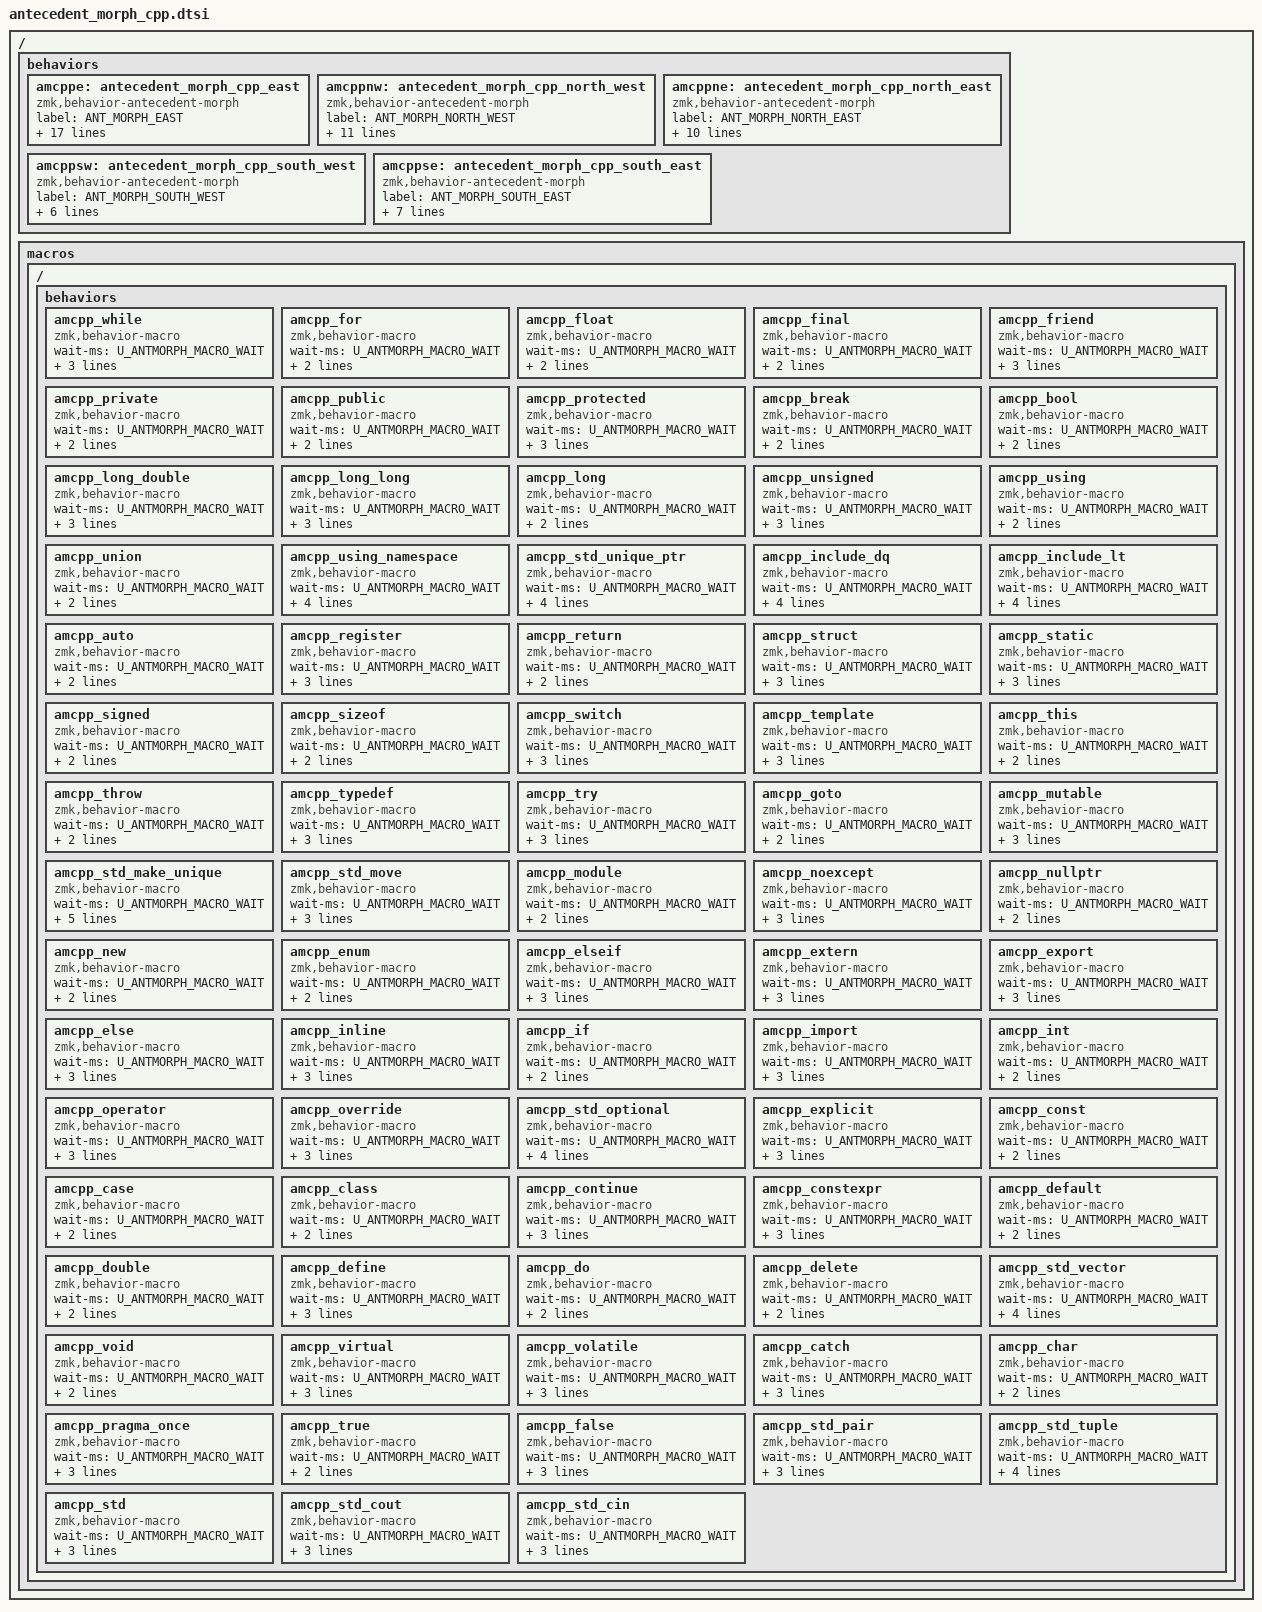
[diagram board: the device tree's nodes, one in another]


/ {
    behaviors {
        amcppe: antecedent_morph_cpp_east {
            compatible = "zmk,behavior-antecedent-morph";
            label = "ANT_MORPH_EAST";
            #binding-cells = <0>;
            defaults = <&none>;
            bindings = <&amcpp_while>, <&amcpp_float>, <&amcpp_public>, <&amcpp_bool>, <&amcpp_long_long>, <&amcpp_using>, 
                        <&amcpp_auto>, <&amcpp_return>, <&amcpp_static>, <&amcpp_this>, <&amcpp_goto>, <&amcpp_std_make_unique>, <&amcpp_nullptr>, <&amcpp_elseif>, <&amcpp_if>, <&amcpp_std_optional>,
                        <&amcpp_explicit>, <&amcpp_const>, <&amcpp_double>, <&amcpp_void>, <&amcpp_catch>, <&amcpp_std_cin>, <&amcpp_std_cout>,
                        <&kp EQUAL>, <&kp EQUAL>, <&kp EQUAL>, <&kp EQUAL>, <&kp EQUAL>, <&kp EQUAL>, <&kp EQUAL>, <&kp EQUAL>, <&amcpp_pragma_once>,
                        <&amcpp_false>, <&amcpp_true>, <&amcpp_std_pair>, <&amcpp_std_tuple>,
                        <&amcpp_std>;
            antecedents = <  W F P B   L U 
                            A R S T G M N E I O
                                X C D V   H DOT COMMA
                            PLUS MINUS EXCLAMATION ASTERISK PIPE PERCENT CARET AMPERSAND LS(N3)
                            N0 N1 N2 N3
                            LS(SEMI)>;
            max-delay-ms = <U_ANTMORPH_DELAY>;
        };
        amcppnw: antecedent_morph_cpp_north_west {
            compatible = "zmk,behavior-antecedent-morph";
            label = "ANT_MORPH_NORTH_WEST";
            #binding-cells = <0>;
            defaults = <&none>;
            bindings = <&amcpp_friend>, <&amcpp_protected>, <&amcpp_long>, <&amcpp_std_unique_ptr>, <&amcpp_include_lt>,
                        <&amcpp_switch>, <&amcpp_try>, <&amcpp_std_move>, <&amcpp_new>, <&amcpp_else>, <&amcpp_int>, <&amcpp_override>,
                        <&amcpp_constexpr>, <&amcpp_delete>, <&amcpp_volatile>, <&amcpp_char>, <&kp EQUAL>, <&kp EQUAL>, <&kp EQUAL>;
            antecedents = <    F P     L U   SQT
                                S T   M N E I O
                                C D V   H DOT COMMA SLASH>;
            max-delay-ms = <U_ANTMORPH_DELAY>;
        };
        amcppne: antecedent_morph_cpp_north_east {
            compatible = "zmk,behavior-antecedent-morph";
            label = "ANT_MORPH_NORTH_EAST";
            #binding-cells = <0>;
            defaults = <&none>;
            bindings = <&amcpp_for>, <&amcpp_private>, <&amcpp_break>, <&amcpp_long_double>, <&amcpp_unsigned>, <&amcpp_include_dq>,
                        <&amcpp_register>, <&amcpp_struct>, <&amcpp_template>, <&amcpp_module>, <&amcpp_enum>, <&amcpp_inline>, <&amcpp_operator>,
                        <&amcpp_case>, <&amcpp_default>, <&amcpp_std_vector>;
            antecedents = <    F P B   L U   SQT
                                R S T   M   E I O
                                C D V>;
            max-delay-ms = <U_ANTMORPH_DELAY>;
        };
        amcppsw: antecedent_morph_cpp_south_west {
            compatible = "zmk,behavior-antecedent-morph";
            label = "ANT_MORPH_SOUTH_WEST";
            #binding-cells = <0>;
            defaults = <&none>;
            bindings = <&amcpp_using_namespace>,
                        <&amcpp_sizeof>, <&amcpp_typedef>, <&amcpp_export>,
                        <&amcpp_continue>, <&amcpp_do>;
            antecedents = <              U     
                                S T       E     
                                C D>;
            max-delay-ms = <U_ANTMORPH_DELAY>;
        };
        amcppse: antecedent_morph_cpp_south_east {
            compatible = "zmk,behavior-antecedent-morph";
            label = "ANT_MORPH_SOUTH_EAST";
            #binding-cells = <0>;
            defaults = <&none>;
            bindings = <&amcpp_final>, <&amcpp_union>,
                        <&amcpp_signed>, <&amcpp_throw>, <&amcpp_mutable>, <&amcpp_extern>, <&amcpp_import>,
                        <&amcpp_class>, <&amcpp_define>, <&amcpp_virtual>;
            antecedents = <    F         U      
                                S T   M   E I
                                C D V>;
            max-delay-ms = <U_ANTMORPH_DELAY>;
        };
    };
    macros {
        ZMK_MACRO(amcpp_while,
            wait-ms = <U_ANTMORPH_MACRO_WAIT>;
            tap-ms = <U_ANTMORPH_MACRO_TAP>;
            bindings = <&kp H &kp I &kp L &kp E &kp SPACE &kp LPAR>; // (w)hile (
        )
        ZMK_MACRO(amcpp_for,
            wait-ms = <U_ANTMORPH_MACRO_WAIT>;
            tap-ms = <U_ANTMORPH_MACRO_TAP>;
            bindings = <&kp O &kp R &kp SPACE &kp LPAR>; // (f)or (
        )
        ZMK_MACRO(amcpp_float,
            wait-ms = <U_ANTMORPH_MACRO_WAIT>;
            tap-ms = <U_ANTMORPH_MACRO_TAP>;
            bindings = <&kp L &kp O &kp A &kp T>; // (f)loat
        )
        ZMK_MACRO(amcpp_final,
            wait-ms = <U_ANTMORPH_MACRO_WAIT>;
            tap-ms = <U_ANTMORPH_MACRO_TAP>;
            bindings = <&kp I &kp N &kp A &kp L>; // (f)inal
        )
        ZMK_MACRO(amcpp_friend,
            wait-ms = <U_ANTMORPH_MACRO_WAIT>;
            tap-ms = <U_ANTMORPH_MACRO_TAP>;
            bindings = <&kp R &kp I &kp E &kp N &kp D &kp SPACE>; // (f)riend 
        )
        ZMK_MACRO(amcpp_private,
            wait-ms = <U_ANTMORPH_MACRO_WAIT>;
            tap-ms = <U_ANTMORPH_MACRO_TAP>;
            bindings = <&kp R &kp I &kp V &kp A &kp T &kp E>; // (p)rivate
        )
        ZMK_MACRO(amcpp_public,
            wait-ms = <U_ANTMORPH_MACRO_WAIT>;
            tap-ms = <U_ANTMORPH_MACRO_TAP>;
            bindings = <&kp U &kp B &kp L &kp I &kp C>; // (p)ublic
        )
        ZMK_MACRO(amcpp_protected,
            wait-ms = <U_ANTMORPH_MACRO_WAIT>;
            tap-ms = <U_ANTMORPH_MACRO_TAP>;
            bindings = <&kp R &kp O &kp T &kp E &kp C &kp T &kp E &kp D>; // (p)rotected
        )
        ZMK_MACRO(amcpp_break,
            wait-ms = <U_ANTMORPH_MACRO_WAIT>;
            tap-ms = <U_ANTMORPH_MACRO_TAP>;
            bindings = <&kp R &kp E &kp A &kp K &kp SEMI>; // (b)reak;
        )
        ZMK_MACRO(amcpp_bool,
            wait-ms = <U_ANTMORPH_MACRO_WAIT>;
            tap-ms = <U_ANTMORPH_MACRO_TAP>;
            bindings = <&kp O &kp O &kp L>; // (b)ool
        )
        ZMK_MACRO(amcpp_long_double,
            wait-ms = <U_ANTMORPH_MACRO_WAIT>;
            tap-ms = <U_ANTMORPH_MACRO_TAP>;
            bindings = <&kp O &kp N &kp G &kp SPACE &kp D &kp O &kp U &kp B &kp L &kp E>; // (l)ong double
        )
        ZMK_MACRO(amcpp_long_long,
            wait-ms = <U_ANTMORPH_MACRO_WAIT>;
            tap-ms = <U_ANTMORPH_MACRO_TAP>;
            bindings = <&kp O &kp N &kp G &kp SPACE &kp L &kp O &kp N &kp G>; // (l)ong long
        )
        ZMK_MACRO(amcpp_long,
            wait-ms = <U_ANTMORPH_MACRO_WAIT>;
            tap-ms = <U_ANTMORPH_MACRO_TAP>;
            bindings = <&kp O &kp N &kp G>; // (l)ong
        )
        ZMK_MACRO(amcpp_unsigned,
            wait-ms = <U_ANTMORPH_MACRO_WAIT>;
            tap-ms = <U_ANTMORPH_MACRO_TAP>;
            bindings = <&kp N &kp S &kp I &kp G &kp N &kp E &kp D>; // (u)nsigned
        )
        ZMK_MACRO(amcpp_using,
            wait-ms = <U_ANTMORPH_MACRO_WAIT>;
            tap-ms = <U_ANTMORPH_MACRO_TAP>; 
            bindings = <&kp S &kp I &kp N &kp G &kp SPACE>; // (u)sing 
        )
        ZMK_MACRO(amcpp_union,
            wait-ms = <U_ANTMORPH_MACRO_WAIT>;
            tap-ms = <U_ANTMORPH_MACRO_TAP>;
            bindings = <&kp N &kp I &kp O &kp N &kp SPACE>; // (u)nion 
        )
        ZMK_MACRO(amcpp_using_namespace,
            wait-ms = <U_ANTMORPH_MACRO_WAIT>;
            tap-ms = <U_ANTMORPH_MACRO_TAP>; 
            bindings = <&kp S &kp I &kp N &kp G &kp SPACE &kp N &kp A &kp M &kp E &kp S &kp P &kp A &kp C &kp E &kp SPACE>; // (u)sing namespace 
        )
        ZMK_MACRO(amcpp_std_unique_ptr,
            wait-ms = <U_ANTMORPH_MACRO_WAIT>;
            tap-ms = <U_ANTMORPH_MACRO_TAP>;
            bindings = <&kp BSPC &kp S &kp T &kp D &kp COLON &kp COLON &kp U &kp N &kp I &kp Q &kp U &kp E &kp UNDER &kp P &kp T &kp R &kp LT>; // [*]std::unique_ptr<
        )
        ZMK_MACRO(amcpp_include_dq,
            wait-ms = <U_ANTMORPH_MACRO_WAIT>;
            tap-ms = <U_ANTMORPH_MACRO_TAP>;
            bindings = <&kp BSPC &kp HASH &kp I &kp N &kp C &kp L &kp U &kp D &kp E &kp SPACE &kp DQT &kp DQT &kp LEFT>; // [']#include ""
        )
        ZMK_MACRO(amcpp_include_lt,
            wait-ms = <U_ANTMORPH_MACRO_WAIT>;
            tap-ms = <U_ANTMORPH_MACRO_TAP>;
            bindings = <&kp BSPC &kp HASH &kp I &kp N &kp C &kp L &kp U &kp D &kp E &kp SPACE &kp LT &kp GT &kp LEFT>; // [']#include <>
        )
        ZMK_MACRO(amcpp_auto,
            wait-ms = <U_ANTMORPH_MACRO_WAIT>;
            tap-ms = <U_ANTMORPH_MACRO_TAP>;
            bindings = <&kp U &kp T &kp O>; // (a)uto
        )
        ZMK_MACRO(amcpp_register,
            wait-ms = <U_ANTMORPH_MACRO_WAIT>;
            tap-ms = <U_ANTMORPH_MACRO_TAP>;
            bindings = <&kp E &kp G &kp I &kp S &kp T &kp E &kp R>; // (r)egister
        )
        ZMK_MACRO(amcpp_return,
            wait-ms = <U_ANTMORPH_MACRO_WAIT>;
            tap-ms = <U_ANTMORPH_MACRO_TAP>;
            bindings = <&kp E &kp T &kp U &kp R &kp N>; // (r)eturn
        )
        ZMK_MACRO(amcpp_struct,
            wait-ms = <U_ANTMORPH_MACRO_WAIT>;
            tap-ms = <U_ANTMORPH_MACRO_TAP>;
            bindings = <&kp T &kp R &kp U &kp C &kp T &kp SPACE>; // (s)truct 
        )
        ZMK_MACRO(amcpp_static,
            wait-ms = <U_ANTMORPH_MACRO_WAIT>;
            tap-ms = <U_ANTMORPH_MACRO_TAP>;
            bindings = <&kp T &kp A &kp T &kp I &kp C &kp SPACE>; // (s)tatic 
        )
        ZMK_MACRO(amcpp_signed,
            wait-ms = <U_ANTMORPH_MACRO_WAIT>;
            tap-ms = <U_ANTMORPH_MACRO_TAP>;
            bindings = <&kp I &kp G &kp N &kp E &kp D>; // (s)igned
        )
        ZMK_MACRO(amcpp_sizeof,
            wait-ms = <U_ANTMORPH_MACRO_WAIT>;
            tap-ms = <U_ANTMORPH_MACRO_TAP>;
            bindings = <&kp I &kp Z &kp E &kp O &kp F>; // (s)izeof
        )
        ZMK_MACRO(amcpp_switch,
            wait-ms = <U_ANTMORPH_MACRO_WAIT>;
            tap-ms = <U_ANTMORPH_MACRO_TAP>;
            bindings = <&kp W &kp I &kp T &kp C &kp H &kp SPACE &kp LPAR>; // (s)witch (
        )
        ZMK_MACRO(amcpp_template,
            wait-ms = <U_ANTMORPH_MACRO_WAIT>;
            tap-ms = <U_ANTMORPH_MACRO_TAP>;
            bindings = <&kp E &kp M &kp P &kp L &kp A &kp T &kp E>; // (t)emplate
        )
        ZMK_MACRO(amcpp_this,
            wait-ms = <U_ANTMORPH_MACRO_WAIT>;
            tap-ms = <U_ANTMORPH_MACRO_TAP>;
            bindings = <&kp H &kp I &kp S>; // (t)his
        )
        ZMK_MACRO(amcpp_throw,
            wait-ms = <U_ANTMORPH_MACRO_WAIT>;
            tap-ms = <U_ANTMORPH_MACRO_TAP>;
            bindings = <&kp H &kp R &kp O &kp W>; // (t)hrow
        )
        ZMK_MACRO(amcpp_typedef,
            wait-ms = <U_ANTMORPH_MACRO_WAIT>;
            tap-ms = <U_ANTMORPH_MACRO_TAP>;
            bindings = <&kp Y &kp P &kp E &kp D &kp E &kp F &kp SPACE>; // (t)ypedef 
        )
        ZMK_MACRO(amcpp_try,
            wait-ms = <U_ANTMORPH_MACRO_WAIT>;
            tap-ms = <U_ANTMORPH_MACRO_TAP>;
            bindings = <&kp R &kp Y &kp SPACE &kp LBRC &kp RET>; // (t)ry {\n
        )
        ZMK_MACRO(amcpp_goto,
            wait-ms = <U_ANTMORPH_MACRO_WAIT>;
            tap-ms = <U_ANTMORPH_MACRO_TAP>;
            bindings = <&kp O &kp T &kp O &kp SPACE>; // (g)oto 
        )
        ZMK_MACRO(amcpp_mutable,
            wait-ms = <U_ANTMORPH_MACRO_WAIT>;
            tap-ms = <U_ANTMORPH_MACRO_TAP>;
            bindings = <&kp U &kp T &kp A &kp B &kp L &kp E &kp SPACE>; // (m)utable 
        )
        ZMK_MACRO(amcpp_std_make_unique,
            wait-ms = <U_ANTMORPH_MACRO_WAIT>;
            tap-ms = <U_ANTMORPH_MACRO_TAP>;
            // [m]std::make_unique<>(
            bindings = <&kp BSPC &kp S &kp T &kp D &kp COLON &kp COLON &kp M &kp A &kp K &kp E &kp UNDER &kp U &kp N &kp I &kp Q &kp U &kp E &kp LT &kp GT &kp LPAR &kp LEFT &kp LEFT>; 
        )
        ZMK_MACRO(amcpp_std_move,
            wait-ms = <U_ANTMORPH_MACRO_WAIT>;
            tap-ms = <U_ANTMORPH_MACRO_TAP>;
            bindings = <&kp BSPC &kp S &kp T &kp D &kp COLON &kp COLON &kp M &kp O &kp V &kp E &kp LPAR>; // [m]std::move(
        )
        ZMK_MACRO(amcpp_module,
            wait-ms = <U_ANTMORPH_MACRO_WAIT>;
            tap-ms = <U_ANTMORPH_MACRO_TAP>;
            bindings = <&kp O &kp D &kp U &kp L &kp E>; // (m)odule
        )
        ZMK_MACRO(amcpp_noexcept,
            wait-ms = <U_ANTMORPH_MACRO_WAIT>;
            tap-ms = <U_ANTMORPH_MACRO_TAP>;
            bindings = <&kp O &kp E &kp X &kp C &kp E &kp P &kp T>; // (n)oexcept
        )
        ZMK_MACRO(amcpp_nullptr,
            wait-ms = <U_ANTMORPH_MACRO_WAIT>;
            tap-ms = <U_ANTMORPH_MACRO_TAP>;
            bindings = <&kp U &kp L &kp L &kp P &kp T &kp R>; // (n)ullptr
        )
        ZMK_MACRO(amcpp_new,
            wait-ms = <U_ANTMORPH_MACRO_WAIT>;
            tap-ms = <U_ANTMORPH_MACRO_TAP>;
            bindings = <&kp E &kp W>; // (n)ew
        )
        ZMK_MACRO(amcpp_enum,
            wait-ms = <U_ANTMORPH_MACRO_WAIT>;
            tap-ms = <U_ANTMORPH_MACRO_TAP>;
            bindings = <&kp N &kp U &kp M &kp SPACE>; // (e)num 
        )
        ZMK_MACRO(amcpp_elseif,
            wait-ms = <U_ANTMORPH_MACRO_WAIT>;
            tap-ms = <U_ANTMORPH_MACRO_TAP>;
            bindings = <&kp L &kp S &kp E &kp SPACE &kp I &kp F &kp SPACE &kp LPAR>; // (e)lse if (
        )
        ZMK_MACRO(amcpp_extern,
            wait-ms = <U_ANTMORPH_MACRO_WAIT>;
            tap-ms = <U_ANTMORPH_MACRO_TAP>;
            bindings = <&kp X &kp T &kp E &kp R &kp N &kp SPACE>; // (e)xtern 
        )
        ZMK_MACRO(amcpp_export,
            wait-ms = <U_ANTMORPH_MACRO_WAIT>;
            tap-ms = <U_ANTMORPH_MACRO_TAP>;
            bindings = <&kp X &kp P &kp O &kp R &kp T &kp SPACE>; // (e)xport 
        )
        ZMK_MACRO(amcpp_else,
            wait-ms = <U_ANTMORPH_MACRO_WAIT>;
            tap-ms = <U_ANTMORPH_MACRO_TAP>;
            bindings = <&kp L &kp S &kp E &kp SPACE &kp LBRC &kp RET>; // (e)lse {\n
        )
        ZMK_MACRO(amcpp_inline,
            wait-ms = <U_ANTMORPH_MACRO_WAIT>;
            tap-ms = <U_ANTMORPH_MACRO_TAP>;
            bindings = <&kp N &kp L &kp I &kp N &kp E &kp SPACE>; // (i)nline 
        )
        ZMK_MACRO(amcpp_if,
            wait-ms = <U_ANTMORPH_MACRO_WAIT>;
            tap-ms = <U_ANTMORPH_MACRO_TAP>;
            bindings = <&kp F &kp SPACE &kp LPAR>; // (i)f (
        )
        ZMK_MACRO(amcpp_import,
            wait-ms = <U_ANTMORPH_MACRO_WAIT>;
            tap-ms = <U_ANTMORPH_MACRO_TAP>;
            bindings = <&kp M &kp P &kp O &kp R &kp T &kp SPACE>; // (i)mport 
        )
        ZMK_MACRO(amcpp_int,
            wait-ms = <U_ANTMORPH_MACRO_WAIT>;
            tap-ms = <U_ANTMORPH_MACRO_TAP>;
            bindings = <&kp N &kp T>; // (i)nt
        )
        ZMK_MACRO(amcpp_operator,
            wait-ms = <U_ANTMORPH_MACRO_WAIT>;
            tap-ms = <U_ANTMORPH_MACRO_TAP>;
            bindings = <&kp P &kp E &kp R &kp A &kp T &kp O &kp R>; // (o)perator
        )
        ZMK_MACRO(amcpp_override,
            wait-ms = <U_ANTMORPH_MACRO_WAIT>;
            tap-ms = <U_ANTMORPH_MACRO_TAP>;
            bindings = <&kp V &kp E &kp R &kp R &kp I &kp D &kp E>; // (o)verride
        )
        ZMK_MACRO(amcpp_std_optional,
            wait-ms = <U_ANTMORPH_MACRO_WAIT>;
            tap-ms = <U_ANTMORPH_MACRO_TAP>;
            bindings = <&kp BSPC &kp S &kp T &kp D &kp COLON &kp COLON &kp O &kp P &kp T &kp I &kp O &kp N &kp A &kp L &kp LT>; // [o]std::optional<
        )
        ZMK_MACRO(amcpp_explicit,
            wait-ms = <U_ANTMORPH_MACRO_WAIT>;
            tap-ms = <U_ANTMORPH_MACRO_TAP>;
            bindings = <&kp BSPC &kp E &kp X &kp P &kp L &kp I &kp C &kp I  &kp T>; // [x]explicit
        )
        ZMK_MACRO(amcpp_const,
            wait-ms = <U_ANTMORPH_MACRO_WAIT>;
            tap-ms = <U_ANTMORPH_MACRO_TAP>;
            bindings = <&kp O &kp N &kp S &kp T>; // (c)onst
        )
        ZMK_MACRO(amcpp_case,
            wait-ms = <U_ANTMORPH_MACRO_WAIT>;
            tap-ms = <U_ANTMORPH_MACRO_TAP>;
            bindings = <&kp A &kp S &kp E &kp SPACE>; // (c)ase 
        )
        ZMK_MACRO(amcpp_class,
            wait-ms = <U_ANTMORPH_MACRO_WAIT>;
            tap-ms = <U_ANTMORPH_MACRO_TAP>;
            bindings = <&kp L &kp A &kp S &kp S &kp SPACE>; // (c)lass 
        )
        ZMK_MACRO(amcpp_continue,
            wait-ms = <U_ANTMORPH_MACRO_WAIT>;
            tap-ms = <U_ANTMORPH_MACRO_TAP>;
            bindings = <&kp O &kp N &kp T &kp I &kp N &kp U &kp E &kp SEMI>; // (c)ontinue;
        )
        ZMK_MACRO(amcpp_constexpr,
            wait-ms = <U_ANTMORPH_MACRO_WAIT>;
            tap-ms = <U_ANTMORPH_MACRO_TAP>;
            bindings = <&kp O &kp N &kp S &kp T &kp E &kp X &kp P &kp R>; // (c)onstexpr
        )
        ZMK_MACRO(amcpp_default,
            wait-ms = <U_ANTMORPH_MACRO_WAIT>;
            tap-ms = <U_ANTMORPH_MACRO_TAP>;
            bindings = <&kp E &kp F &kp A &kp U &kp L &kp T>; // (d)efault
        )
        ZMK_MACRO(amcpp_double,
            wait-ms = <U_ANTMORPH_MACRO_WAIT>;
            tap-ms = <U_ANTMORPH_MACRO_TAP>;
            bindings = <&kp O &kp U &kp B &kp L &kp E>; // (d)ouble
        )
        ZMK_MACRO(amcpp_define,
            wait-ms = <U_ANTMORPH_MACRO_WAIT>;
            tap-ms = <U_ANTMORPH_MACRO_TAP>;
            bindings = <&kp BSPC &kp HASH &kp D &kp E &kp F &kp I &kp N &kp E &kp SPACE>; // [d]#define 
        )
        ZMK_MACRO(amcpp_do,
            wait-ms = <U_ANTMORPH_MACRO_WAIT>;
            tap-ms = <U_ANTMORPH_MACRO_TAP>;
            bindings = <&kp O &kp SPACE &kp LBRC &kp RET>; // (d)o {\n
        )
        ZMK_MACRO(amcpp_delete,
            wait-ms = <U_ANTMORPH_MACRO_WAIT>;
            tap-ms = <U_ANTMORPH_MACRO_TAP>;
            bindings = <&kp E &kp L &kp E &kp T &kp E>; // (d)elete
        )
        ZMK_MACRO(amcpp_std_vector,
            wait-ms = <U_ANTMORPH_MACRO_WAIT>;
            tap-ms = <U_ANTMORPH_MACRO_TAP>;
            bindings = <&kp BSPC &kp S &kp T &kp D &kp COLON &kp COLON &kp V &kp E &kp C &kp T &kp O &kp R &kp LT>; // [v]std::vector< 
        )
        ZMK_MACRO(amcpp_void,
            wait-ms = <U_ANTMORPH_MACRO_WAIT>;
            tap-ms = <U_ANTMORPH_MACRO_TAP>;
            bindings = <&kp O &kp I &kp D>; // (v)oid
        )
        ZMK_MACRO(amcpp_virtual,
            wait-ms = <U_ANTMORPH_MACRO_WAIT>;
            tap-ms = <U_ANTMORPH_MACRO_TAP>;
            bindings = <&kp I &kp R &kp T &kp U &kp A &kp L &kp SPACE>; // (v)irtual 
        )
        ZMK_MACRO(amcpp_volatile,
            wait-ms = <U_ANTMORPH_MACRO_WAIT>;
            tap-ms = <U_ANTMORPH_MACRO_TAP>;
            bindings = <&kp O &kp L &kp A &kp T &kp I &kp L &kp E>; // (v)olatile
        )
        ZMK_MACRO(amcpp_catch,
            wait-ms = <U_ANTMORPH_MACRO_WAIT>;
            tap-ms = <U_ANTMORPH_MACRO_TAP>;
            bindings = <&kp BSPC &kp C &kp A &kp T &kp C &kp H &kp SPACE &kp LPAR>; // [h]catch (
        )
        ZMK_MACRO(amcpp_char,
            wait-ms = <U_ANTMORPH_MACRO_WAIT>;
            tap-ms = <U_ANTMORPH_MACRO_TAP>;
            bindings = <&kp BSPC &kp C &kp H &kp A &kp R>; // [h]char
        )
        ZMK_MACRO(amcpp_pragma_once,
            wait-ms = <U_ANTMORPH_MACRO_WAIT>;
            tap-ms = <U_ANTMORPH_MACRO_TAP>;
            bindings = <&kp P &kp R &kp A &kp G &kp M &kp A &kp SPACE &kp O &kp N &kp C &kp E>; // (#)pragma once
        )
        ZMK_MACRO(amcpp_true,
            wait-ms = <U_ANTMORPH_MACRO_WAIT>;
            tap-ms = <U_ANTMORPH_MACRO_TAP>;
            bindings = <&kp BSPC &kp T &kp R &kp U &kp E>; // [1]true
        )
        ZMK_MACRO(amcpp_false,
            wait-ms = <U_ANTMORPH_MACRO_WAIT>;
            tap-ms = <U_ANTMORPH_MACRO_TAP>;
            bindings = <&kp BSPC &kp F &kp A &kp L &kp S &kp E>; // [0]false
        )
        ZMK_MACRO(amcpp_std_pair,
            wait-ms = <U_ANTMORPH_MACRO_WAIT>;
            tap-ms = <U_ANTMORPH_MACRO_TAP>;
            bindings = <&kp BSPC &kp S &kp T &kp D &kp COLON &kp COLON &kp P &kp A &kp I &kp R &kp LT>; // [2]std::pair<
        )
        ZMK_MACRO(amcpp_std_tuple,
            wait-ms = <U_ANTMORPH_MACRO_WAIT>;
            tap-ms = <U_ANTMORPH_MACRO_TAP>;
            bindings = <&kp BSPC &kp S &kp T &kp D &kp COLON &kp COLON &kp T &kp U &kp P &kp L &kp E &kp LT>; // [3]std::tuple<
        )
        ZMK_MACRO(amcpp_std,
            wait-ms = <U_ANTMORPH_MACRO_WAIT>;
            tap-ms = <U_ANTMORPH_MACRO_TAP>;
            bindings = <&kp BSPC &kp S &kp T &kp D &kp COLON &kp COLON>; // [:]std::
        )
        ZMK_MACRO(amcpp_std_cout,
            wait-ms = <U_ANTMORPH_MACRO_WAIT>;
            tap-ms = <U_ANTMORPH_MACRO_TAP>;
            bindings = <&kp BSPC &kp S &kp T &kp D &kp COLON &kp COLON &kp C &kp O &kp U &kp T>; // [<]std::cout
        )
        ZMK_MACRO(amcpp_std_cin,
            wait-ms = <U_ANTMORPH_MACRO_WAIT>;
            tap-ms = <U_ANTMORPH_MACRO_TAP>;
            bindings = <&kp BSPC &kp S &kp T &kp D &kp COLON &kp COLON &kp C &kp I &kp N>; // [>]std::cin
        )
    };
};
